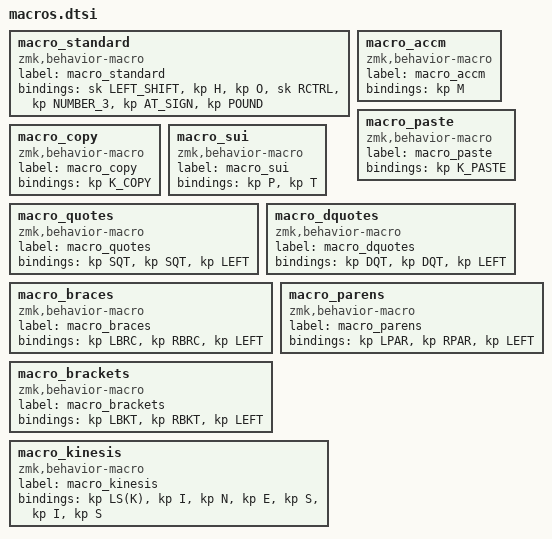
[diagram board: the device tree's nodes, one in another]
macro_standard: macro_standard{
compatible = "zmk,behavior-macro";
label = "macro_standard";
#binding-cells = <0>;
bindings = <&sk LEFT_SHIFT>, <&kp H>, <&kp O>, <&sk RCTRL>, <&kp NUMBER_3>, <&kp AT_SIGN>, <&kp POUND>;
};
macro_accm: macro_accm{
compatible = "zmk,behavior-macro";
label = "macro_accm";
#binding-cells = <0>;
bindings = <&kp M>;
};
macro_paste: macro_paste{
compatible = "zmk,behavior-macro";
label = "macro_paste";
#binding-cells = <0>;
bindings = <&kp K_PASTE>;
};
macro_copy: macro_copy{
compatible = "zmk,behavior-macro";
label = "macro_copy";
#binding-cells = <0>;
bindings = <&kp K_COPY>;
};
macro_sui: macro_sui{
compatible = "zmk,behavior-macro";
label = "macro_sui";
#binding-cells = <0>;
bindings = <&kp P>, <&kp T>;
};
macro_quotes: macro_quotes{
compatible = "zmk,behavior-macro";
label = "macro_quotes";
#binding-cells = <0>;
bindings = <&kp SQT>, <&kp SQT>, <&kp LEFT>;
};
macro_dquotes: macro_dquotes{
compatible = "zmk,behavior-macro";
label = "macro_dquotes";
#binding-cells = <0>;
bindings = <&kp DQT>, <&kp DQT>, <&kp LEFT>;
};
macro_braces: macro_braces{
compatible = "zmk,behavior-macro";
label = "macro_braces";
#binding-cells = <0>;
bindings = <&kp LBRC>, <&kp RBRC>, <&kp LEFT>;
};
macro_parens: macro_parens{
compatible = "zmk,behavior-macro";
label = "macro_parens";
#binding-cells = <0>;
bindings = <&kp LPAR>, <&kp RPAR>, <&kp LEFT>;
};
macro_brackets: macro_brackets{
compatible = "zmk,behavior-macro";
label = "macro_brackets";
#binding-cells = <0>;
bindings = <&kp LBKT>, <&kp RBKT>, <&kp LEFT>;
};
macro_kinesis: macro_kinesis{
compatible = "zmk,behavior-macro";
label = "macro_kinesis";
#binding-cells = <0>;
bindings = <&kp LS(K)>, <&kp I>, <&kp N>, <&kp E>, <&kp S>, <&kp I>, <&kp S>;
};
